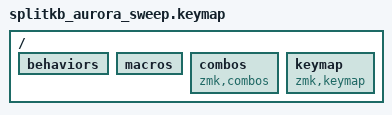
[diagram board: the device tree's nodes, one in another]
/*
*
* Copyright (c) 2024 Denis Bekasow
* SPDX-License-Identifier: MIT
*
*/

#include <behaviors.dtsi>
#include <dt-bindings/zmk/keys.h>
#include <dt-bindings/zmk/bt.h>

#include "common/keypos_def.h"
#include "common/layers_def.h"
#include "common/config.dtsi"

#include "layouts/de/keymap.h"

/ {
	behaviors {
		#include "features/homerows.dtsi"
		#include "features/overrides.dtsi"
		#include "features/adaptives.dtsi"
	};

	macros {
		#include "features/macros.dtsi"
	};
	
	combos {
		compatible = "zmk,combos";
		#include "features/combos.dtsi"
	};

	keymap {
		compatible = "zmk,keymap";
		#include "layers/base.dtsi"
		#include "layers/symbol.dtsi"
		#include "layers/math.dtsi"
		#include "layers/number.dtsi"
		#include "layers/navigation.dtsi"
	 	#include "layers/function.dtsi"
	 	#include "layers/mirror.dtsi"
	};
};
